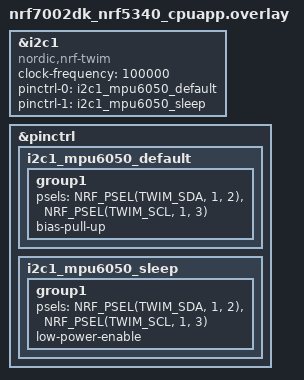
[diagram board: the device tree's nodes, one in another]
#include <zephyr/dt-bindings/pinctrl/nrf-pinctrl.h>

&i2c1 {
    compatible = "nordic,nrf-twim";
    status = "okay";
    clock-frequency = <100000>;

    pinctrl-0 = <&i2c1_mpu6050_default>;
    pinctrl-1 = <&i2c1_mpu6050_sleep>;
    pinctrl-names = "default", "sleep";
};

&pinctrl {
    i2c1_mpu6050_default: i2c1_mpu6050_default {
        group1 {
            psels = <NRF_PSEL(TWIM_SDA, 1, 2)>,
                    <NRF_PSEL(TWIM_SCL, 1, 3)>;
            bias-pull-up;
        };
    };

    i2c1_mpu6050_sleep: i2c1_mpu6050_sleep {
        group1 {
            psels = <NRF_PSEL(TWIM_SDA, 1, 2)>,
                    <NRF_PSEL(TWIM_SCL, 1, 3)>;
            low-power-enable;
        };
    };
};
